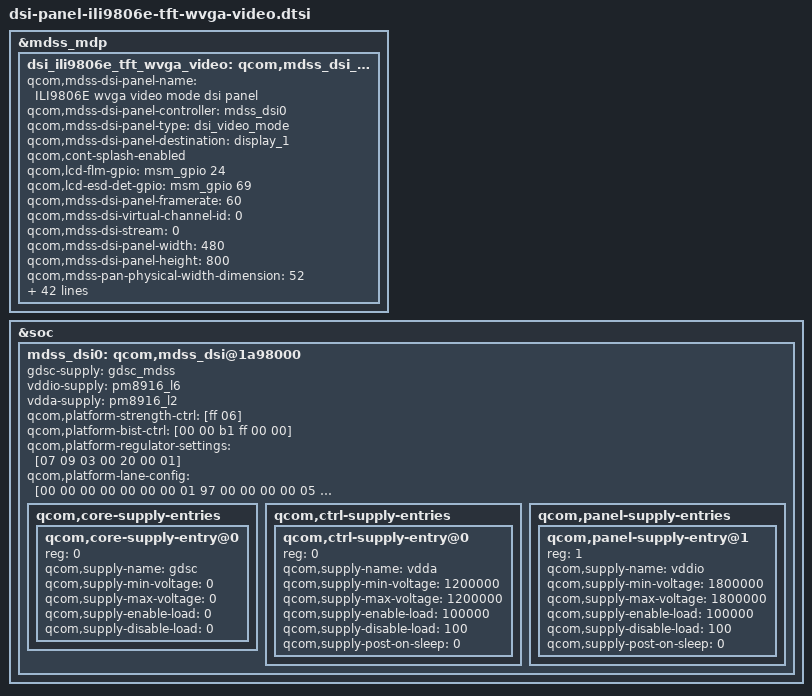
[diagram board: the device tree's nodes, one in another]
/* Copyright (c) 2013-14, Samsung Electronics Corporation. All rights reserved.
 *
 * This program is free software; you can redistribute it and/or modify
 * it under the terms of the GNU General Public License version 2 and
 * only version 2 as published by the Free Software Foundation.
 *
 * This program is distributed in the hope that it will be useful,
 * but WITHOUT ANY WARRANTY; without even the implied warranty of
 * MERCHANTABILITY or FITNESS FOR A PARTICULAR PURPOSE.  See the
 * GNU General Public License for more details.
 */

/*---------------------------------------------------------------------------
 * This file is autogenerated file using gcdb parser. Please do not edit it.
 * Update input XML file to add a new entry or update variable in this file
 * VERSION = "1.0"
 *---------------------------------------------------------------------------

 */
&mdss_mdp {
	dsi_ili9806e_tft_wvga_video: qcom,mdss_dsi_ili9806e_wvga_video {
		qcom,mdss-dsi-panel-name = "ILI9806E wvga video mode dsi panel";
		qcom,mdss-dsi-panel-controller = <&mdss_dsi0>;
		qcom,mdss-dsi-panel-type = "dsi_video_mode";
		qcom,mdss-dsi-panel-destination = "display_1";
		qcom,cont-splash-enabled;
		qcom,lcd-flm-gpio = <&msm_gpio 24 0>;
		qcom,lcd-esd-det-gpio = <&msm_gpio 69 0>;
		qcom,mdss-dsi-panel-framerate = <60>;
		qcom,mdss-dsi-virtual-channel-id = <0>;
		qcom,mdss-dsi-stream = <0>;
		qcom,mdss-dsi-panel-width = <480>;
		qcom,mdss-dsi-panel-height = <800>;
		qcom,mdss-pan-physical-width-dimension = <52>; /* <Width> real size of panel in mm */
		qcom,mdss-pan-physical-height-dimension = <87>; /*<Height> real size of panel in mm */
		qcom,mdss-dsi-lp11-init;
		qcom,mdss-dsi-init-delay-us = <100>;
		qcom,mdss-dsi-h-front-porch = <110>;
		qcom,mdss-dsi-h-back-porch = <246>;
		qcom,mdss-dsi-h-pulse-width = <4>;
		qcom,mdss-dsi-h-sync-skew = <0>;
		qcom,mdss-dsi-v-back-porch = <12>;
		qcom,mdss-dsi-v-front-porch = <10>;
		qcom,mdss-dsi-v-pulse-width = <4>;
		qcom,mdss-dsi-h-left-border = <0>;
		qcom,mdss-dsi-h-right-border = <0>;
		qcom,mdss-dsi-v-top-border = <0>;
		qcom,mdss-dsi-v-bottom-border = <0>;
		qcom,mdss-dsi-bpp = <24>;
		qcom,mdss-dsi-color-order = <0>;
		qcom,mdss-dsi-underflow-color = <0xff>;
		qcom,mdss-dsi-border-color = <0>;
		qcom,mdss-dsi-dma-trigger = "trigger_sw";
		qcom,mdss-dsi-mdp-trigger = "none";
		qcom,mdss-dsi-bl-min-level = <0>;
		qcom,mdss-dsi-bl-max-level = <100>;
		qcom,mdss-dsi-lane-0-state;
		qcom,mdss-dsi-lane-1-state;
		qcom,mdss-dsi-bllp-eof-power-mode;
		qcom,mdss-dsi-bllp-power-mode;
		qcom,mdss-dsi-traffic-mode = "burst_mode";
		qcom,mdss-force-clk-lane-hs = <0>;
		qcom,mdss-dsi-reset-sequence = <1 20>, <0 1>, <1 20>;
		qcom,mdss-dsi-h-sync-pulse = <0>;
		qcom,mdss-dsi-panel-timings = [88 33 14 00 45 4A 19 37 23 03 04 00];
		qcom,mdss-dsi-t-clk-pre = <0x1D>;
		qcom,mdss-dsi-t-clk-post = <0x04>;
		qcom,mdss-dsi-on-command = [
					39 01 00 00 00 00 06
						FF FF 98 06 04 01
					/* interface setting */
					39 01 00 00 00 00 02
					08 10
					/* GIP1 */
					39 01 00 00 00 00 02
					21 01
					/* GIP2 */
					39 01 00 00 00 00 02
					30 02
					/* GIP3 */
					39 01 00 00 00 00 02
					31 02
					/**/
					39 01 00 00 00 00 02
					40 10
					/**/
					39 01 00 00 00 00 02
					41 22
					/**/
					39 01 00 00 00 00 02
					42 01
					/**/
					39 01 00 00 00 00 02
					43 09
					/**/
					39 01 00 00 00 00 02
					44 06
					/**/
					39 01 00 00 00 00 02
					45 16
					/**/
					39 01 00 00 00 00 02
					50 70
					/**/
					39 01 00 00 00 00 02
					51 70
					/**/
					39 01 00 00 00 00 02
					52 00
					/**/
					39 01 00 00 00 00 02
					53 74
					/**/
					39 01 00 00 00 00 02
					57 50					
					/**/
					39 01 00 00 00 00 02
					60 07
					/**/
					39 01 00 00 00 00 02
					61 00
					/**/
					39 01 00 00 00 00 02
					62 07
					/**/
					39 01 00 00 00 00 02
					63 00
					/*Posi Gamma*/
					39 01 00 00 00 00 02
					A0 00
					39 01 00 00 00 00 02
					A1 02
					39 01 00 00 00 00 02
					A2 0C
					39 01 00 00 00 00 02
					A3 0B
					39 01 00 00 00 00 02
					A4 03
					39 01 00 00 00 00 02
					A5 13
					39 01 00 00 00 00 02
					A6 0A
					39 01 00 00 00 00 02
					A7 09
					39 01 00 00 00 00 02
					A8 04
					39 01 00 00 00 00 02
					A9 09
					39 01 00 00 00 00 02
					AA 07
					39 01 00 00 00 00 02
					AB 04
					39 01 00 00 00 00 02
					AC 0F
					39 01 00 00 00 00 02
					AD 2E
					39 01 00 00 00 00 02
					AE 27
					39 01 00 00 00 00 02
					AF 00
					/*Nega Gamma*/
					39 01 00 00 00 00 02
					C0 00
					39 01 00 00 00 00 02
					C1 06
					39 01 00 00 00 00 02
					C2 06
					39 01 00 00 00 00 02
					C3 0D
					39 01 00 00 00 00 02
					C4 09
					39 01 00 00 00 00 02
					C5 11
					39 01 00 00 00 00 02
					C6 09
					39 01 00 00 00 00 02
					C7 07
					39 01 00 00 00 00 02
					C8 04
					39 01 00 00 00 00 02
					C9 08
					39 01 00 00 00 00 02
					CA 07
					39 01 00 00 00 00 02
					CB 04
					39 01 00 00 00 00 02
					CC 0B
					39 01 00 00 00 00 02
					CD 2A
					39 01 00 00 00 00 02
					CE 24
					39 01 00 00 00 00 02
					CF 00
					/*Change to Page6 Command*/
					39 01 00 00 00 00 06
					FF FF 98 06 04 06
					/*GIP Setting*/
					39 01 00 00 00 00 02
					00 20
					39 01 00 00 00 00 02
					01 0A
					39 01 00 00 00 00 02
					02 00
					39 01 00 00 00 00 02
					03 00
					39 01 00 00 00 00 02
					04 01
					39 01 00 00 00 00 02
					05 01
					39 01 00 00 00 00 02
					06 98
					39 01 00 00 00 00 02
					07 06
					39 01 00 00 00 00 02
					08 01
					39 01 00 00 00 00 02
					09 80
					39 01 00 00 00 00 02
					0A 00
					39 01 00 00 00 00 02
					0B 00
					39 01 00 00 00 00 02
					0C 01
					39 01 00 00 00 00 02
					0D 01
					39 01 00 00 00 00 02
					0E 00
					39 01 00 00 00 00 02
					0F 00
					39 01 00 00 00 00 02
					10 F0
					39 01 00 00 00 00 02
					11 F4
					39 01 00 00 00 00 02
					12 01
					39 01 00 00 00 00 02
					13 00
					39 01 00 00 00 00 02
					14 00
					39 01 00 00 00 00 02
					15 C0
					39 01 00 00 00 00 02
					16 08
					39 01 00 00 00 00 02
					17 00
					39 01 00 00 00 00 02
					18 00
					39 01 00 00 00 00 02
					19 00
					39 01 00 00 00 00 02
					1A 00
					39 01 00 00 00 00 02
					1B 00
					39 01 00 00 00 00 02
					1C 00
					39 01 00 00 00 00 02
					1D 00
					39 01 00 00 00 00 02
					20 01
					39 01 00 00 00 00 02
					21 23
					39 01 00 00 00 00 02
					22 45
					39 01 00 00 00 00 02
					23 67
					39 01 00 00 00 00 02
					24 01
					39 01 00 00 00 00 02
					25 23
					39 01 00 00 00 00 02
					26 45
					39 01 00 00 00 00 02
					27 67
					39 01 00 00 00 00 02
					30 11
					39 01 00 00 00 00 02
					31 11
					39 01 00 00 00 00 02
					32 00
					39 01 00 00 00 00 02
					33 EE
					39 01 00 00 00 00 02
					34 FF
					39 01 00 00 00 00 02
					35 BB
					39 01 00 00 00 00 02
					36 AA
					39 01 00 00 00 00 02
					37 DD
					39 01 00 00 00 00 02
					38 CC
					39 01 00 00 00 00 02
					39 66
					39 01 00 00 00 00 02
					3A 77
					39 01 00 00 00 00 02
					3B 22
					39 01 00 00 00 00 02
					3C 22
					39 01 00 00 00 00 02
					3D 22
					39 01 00 00 00 00 02
					3E 22
					39 01 00 00 00 00 02
					3F 22
					39 01 00 00 00 00 02
					40 22
					39 01 00 00 00 00 02
					52 10
					39 01 00 00 00 00 02
					53 10
					/*Change to Page7 Command*/
					39 01 00 00 00 00 06
					FF FF 98 06 04 07
					/*VGL_REG_EN*/
					39 01 00 00 00 00 02
					17 32
					39 01 00 00 00 00 02
					02 77
					39 01 00 00 00 00 02
					E1 79
					39 01 00 00 00 00 02
					67 20
  					/*Change to Page0 Command*/
					39 01 00 00 00 00 06
					FF FF 98 06 04 00
					/* interface setting */
					39 01 00 00 00 00 02
					36 03
					/* Sleep out */
					05 01 00 00 78 00 02
					11 00
					/* Display on */
					05 01 00 00 0A 00 02
					29 00
					/* Display on */
					05 01 00 00 0A 00 02
					35 00					
					];

		samsung,panel-manufacture-id-read-cmds = [06 01 00 00 00 00 01 da 01
							06 01 00 00 00 00 01 db 01
							06 01 00 00 00 00 01 dc 01];

		qcom,mdss-dsi-on-command-state = "dsi_lp_mode";
		qcom,mdss-dsi-off-command-state = "dsi_hs_mode";
		qcom,mdss-dsi-off-command = [39 01 00 10  00 02 28 00
					39 01 00 00 46 00 02 10 00];
	};
};
&soc {
	mdss_dsi0: qcom,mdss_dsi@1a98000 {
		gdsc-supply = <&gdsc_mdss>;
		vddio-supply = <&pm8916_l6>;
		vdda-supply = <&pm8916_l2>;
		qcom,platform-strength-ctrl = [ff 06];
		qcom,platform-bist-ctrl = [00 00 b1 ff 00 00];
		qcom,platform-regulator-settings = [07 09 03 00 20 00 01];
		qcom,platform-lane-config = [00 00 00 00 00 00 00 01 97
			00 00 00 00 05 00 00 01 97
			00 00 00 00 0a 00 00 01 97
			00 00 00 00 0f 00 00 01 97
			00 c0 00 00 00 00 00 01 bb];
		qcom,core-supply-entries {
			#address-cells = <1>;
			#size-cells = <0>;

			qcom,core-supply-entry@0 {
				reg = <0>;
				qcom,supply-name = "gdsc";
				qcom,supply-min-voltage = <0>;
				qcom,supply-max-voltage = <0>;
				qcom,supply-enable-load = <0>;
				qcom,supply-disable-load = <0>;
			};
		};
		qcom,ctrl-supply-entries {
			#address-cells = <1>;
			#size-cells = <0>;

			qcom,ctrl-supply-entry@0 {
				reg = <0>;
				qcom,supply-name = "vdda";
				qcom,supply-min-voltage = <1200000>;
				qcom,supply-max-voltage = <1200000>;
				qcom,supply-enable-load = <100000>;
				qcom,supply-disable-load = <100>;
				qcom,supply-post-on-sleep = <0>;
			};
		};
		qcom,panel-supply-entries {
			#address-cells = <1>;
			#size-cells = <0>;

			qcom,panel-supply-entry@1 {
				reg = <1>;
				qcom,supply-name = "vddio";
				qcom,supply-min-voltage = <1800000>;
				qcom,supply-max-voltage = <1800000>;
				qcom,supply-enable-load = <100000>;
				qcom,supply-disable-load = <100>;
				qcom,supply-post-on-sleep = <0>;
			};
		};
	};
};

